# PIC18F57Q84 register map
Vendor: Microchip
Registers are 8-bit, read-write, reset 0x0 unless marked. A register's access mark holds for its fields unless they carry their own. Addresses are absolute, and some are shared; only a register's first bit layout is shown; [hi:lo] are bit positions; {n}, {i} and the like mark numbered series.

## SFR
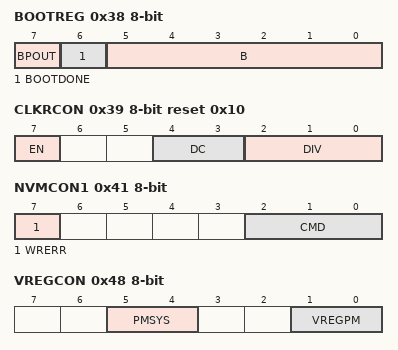
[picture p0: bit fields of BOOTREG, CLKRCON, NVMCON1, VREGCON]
0x38 BOOTREG reset not defined — (power-on value xxxxxxxx)
  [7] BPOUT, [6] BOOTDONE, [5:0] B
0x39 CLKRCON reset 0x10
  [7] EN, [4:3] DC, [2:0] DIV
0x3A CLKRCLK
  [4:0] CLK
0x40 NVMCON0 reset not defined — (power-on value -------x)
  [0] GO
0x41 NVMCON1 reset not defined — (power-on value x----xxx)
  [7] WRERR, [2:0] CMD
0x42 NVMLOCK
  [7:0] LOCK
0x43 NVMADRL
0x44 NVMADRH
0x45 NVMADRU
  [5:0] NVMADRU
0x46 NVMDATL
0x47 NVMDATH
0x48 VREGCON reset not defined — (power-on value --qq--10)
  [5:4] PMSYS ro, [1:0] VREGPM
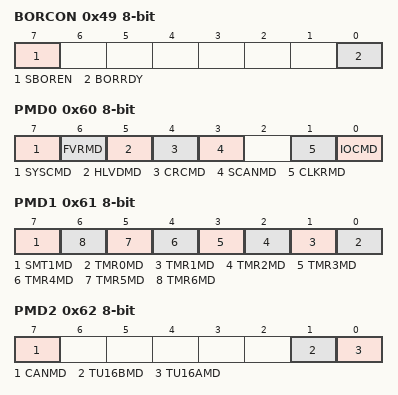
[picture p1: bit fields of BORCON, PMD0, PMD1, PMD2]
0x49 BORCON reset not defined — (power-on value 1------q)
  [7] SBOREN, [0] BORRDY ro
0x60 PMD0
  [7] SYSCMD, [6] FVRMD, [5] HLVDMD, [4] CRCMD, [3] SCANMD, [1] CLKRMD, [0] IOCMD
0x61 PMD1
  [7] SMT1MD, [n] TMR{n}MD (n=0..6)
0x62 PMD2 reset not defined — (power-on value x-----xx)
  [7] CANMD, [1] TU16BMD, [0] TU16AMD
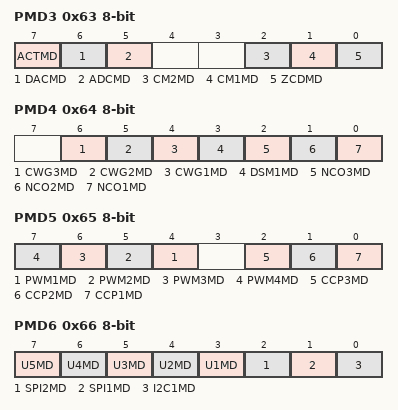
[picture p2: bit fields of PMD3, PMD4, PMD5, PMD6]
0x63 PMD3
  [7] ACTMD, [6] DACMD, [5] ADCMD, [2] CM2MD, [1] CM1MD, [0] ZCDMD
0x64 PMD4 reset not defined — (power-on value 0xxxxxxx)
  [6] CWG3MD, [5] CWG2MD, [4] CWG1MD, [3] DSM1MD, [2] NCO3MD, [1] NCO2MD, [0] NCO1MD
0x65 PMD5 reset not defined — (power-on value xxxx-xxx)
  [n+3] PWM{n}MD (n=1..4), [2] CCP3MD, [1] CCP2MD, [0] CCP1MD
0x66 PMD6 reset not defined — (power-on value xxxxxxxx)
  [n+2] U{n}MD (n=1..5), [2] SPI2MD, [1] SPI1MD, [0] I2C1MD
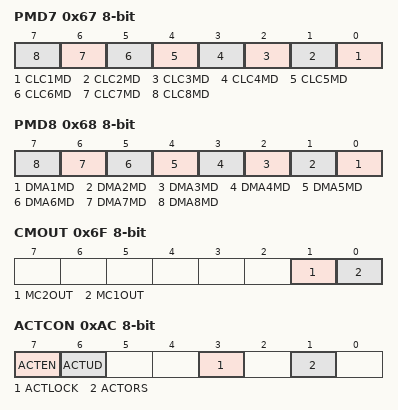
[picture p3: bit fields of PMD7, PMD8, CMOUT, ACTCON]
0x67 PMD7
  [n-1] CLC{n}MD (n=1..8)
0x68 PMD8 reset not defined — (power-on value xx000000)
  [n-1] DMA{n}MD (n=1..8)
0x6F CMOUT ro
  [1] MC2OUT, [0] MC1OUT
0xAC ACTCON
  [7] ACTEN, [6] ACTUD, [3] ACTLOCK ro, [1] ACTORS ro
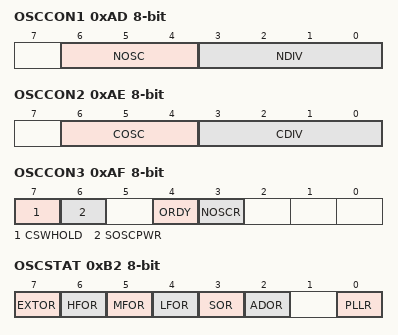
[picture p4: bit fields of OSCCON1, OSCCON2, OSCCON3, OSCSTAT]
0xAD OSCCON1 reset not defined — (power-on value -qqqqqqq)
  [6:4] NOSC, [3:0] NDIV
0xAE OSCCON2 ro reset not defined — (power-on value -qqqqqqq)
  [6:4] COSC, [3:0] CDIV
0xAF OSCCON3
  [7] CSWHOLD, [6] SOSCPWR, [4] ORDY ro, [3] NOSCR ro
0xB0 OSCTUNE
  [5:0] TUN
0xB1 OSCFRQ reset not defined — (power-on value ----q0q0)
  [3:0] HFFRQ
0xB2 OSCSTAT ro reset not defined — (power-on value qqqqqq-q)
  [7] EXTOR, [6] HFOR, [5] MFOR, [4] LFOR, [3] SOR, [2] ADOR, [0] PLLR
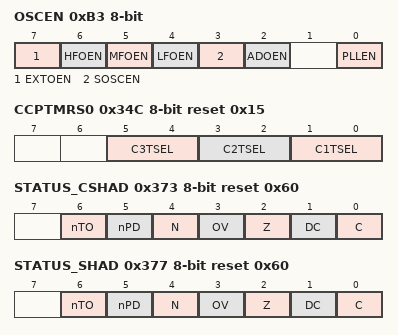
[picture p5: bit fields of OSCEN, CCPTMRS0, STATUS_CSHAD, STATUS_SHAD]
0xB3 OSCEN
  [7] EXTOEN, [6] HFOEN, [5] MFOEN, [4] LFOEN, [3] SOSCEN, [2] ADOEN, [0] PLLEN
0xB4 PRLOCK
  [0] PRLOCKED
0xB5 SCANPR reset 0x7
  [2:0] PR
{0xB5+i} DMA{i}PR reset 0x7 (i=1..6)
  [2:0] PR
0xBC DMA7PR reset not defined — (power-on value -----xxx)
  [2:0] PR
0xBD DMA8PR reset not defined — (power-on value -----xxx)
  [2:0] PR
0xBE MAINPR reset 0x7
  [2:0] PR
0xBF ISRPR reset 0x7
  [2:0] PR
0xD4 CLCDATA reset not defined — (power-on value xxxxxxxx)
  [7:0] MCLC
0x200 PPSLOCK
  [0] PPSLOCKED
0x34C CCPTMRS0 reset 0x15
  [5:4] C3TSEL, [3:2] C2TSEL, [1:0] C1TSEL
0x353 CRCOUTL
  [7:0] OUT
0x353 CRCSHFTL ro
  [7:0] SHIFT
0x353 CRCXORL
  [7:0] XOR
0x354 CRCOUTH
  [7:0] OUT
0x354 CRCSHFTH ro
  [7:0] SHIFT
0x354 CRCXORH
  [7:0] XOR
0x355 CRCOUTU
  [7:0] OUT
0x355 CRCSHFTU ro
  [7:0] SHIFT
0x355 CRCXORU
  [7:0] XOR
0x356 CRCOUTT
  [7:0] OUT
0x356 CRCSHFTT ro
  [7:0] SHIFT
0x356 CRCXORT
  [7:0] XOR
0x373 STATUS_CSHAD reset 0x60
  [6] nTO ro, [5] nPD ro, [4] N, [3] OV, [2] Z, [1] DC, [0] C
0x374 WREG_CSHAD reset not defined — (power-on value xxxxxxxx)
  [7:0] WREG
0x375 BSR_CSHAD
  [5:0] BSR
0x376 SHADCON
  [0] SHADLO
0x377 STATUS_SHAD reset 0x60
  [6] nTO ro, [5] nPD ro, [4] N, [3] OV, [2] Z, [1] DC, [0] C
0x378 WREG_SHAD reset not defined — (power-on value xxxxxxxx)
  [7:0] WREG
0x379 BSR_SHAD
  [5:0] BSR
0x37A PCLATH_SHAD
  [7:0] PCH
0x37B PCLATU_SHAD
  [4:0] PCU
{0x37C+2i} FSR{i}L_SHAD (i=0..2)
  [7:0] FSR{i}L
{0x37D+2i} FSR{i}H_SHAD (i=0..2)
  [5:0] FSR{i}H
0x382 PRODL_SHAD reset not defined — (power-on value xxxxxxxx)
  [7:0] PRODL
0x383 PRODH_SHAD reset not defined — (power-on value xxxxxxxx)
  [7:0] PRODH
0x38B TU16ATMRL
  [7:0] TMRL
0x38B TU16ACRL ro
  [7:0] CRL
0x38C TU16ATMRH
  [7:0] TMRH
0x38C TU16ACRH ro
  [7:0] CRH
0x397 TU16BTMRL
  [7:0] TMRL
0x397 TU16BCRL ro
  [7:0] CRL
0x398 TU16BTMRH
  [7:0] TMRH
0x398 TU16BCRH ro
  [7:0] CRH
0x3BB TUCHAIN reset not defined — (power-on value -------x)
  [0] CH16AB
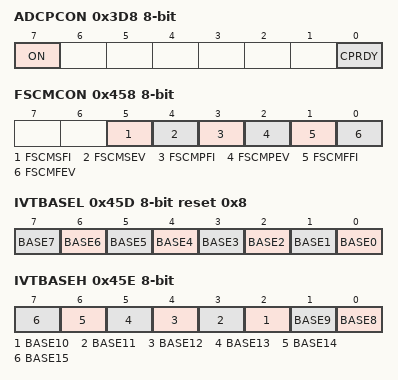
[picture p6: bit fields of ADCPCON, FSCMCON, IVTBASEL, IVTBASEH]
0x3D8 ADCPCON reset not defined — (power-on value x------x)
  [7] ON, [0] CPRDY ro
0x458 FSCMCON reset not defined — (power-on value --xxxxxx)
  [5] FSCMSFI, [4] FSCMSEV, [3] FSCMPFI, [2] FSCMPEV, [1] FSCMFFI, [0] FSCMFEV
0x459 IVTLOCK
  [0] IVTLOCKED
0x45A IVTADL reset not defined — (power-on value xxxxxxxx)
  [7:0] AD
0x45B IVTADH reset not defined — (power-on value xxxxxxxx)
  [7:0] AD
0x45C IVTADU reset not defined — (power-on value xxxxxxxx)
  [7:0] AD
0x45D IVTBASEL reset 0x8
  [n] BASE{n} (n=0..7)
0x45E IVTBASEH
  [n-8] BASE{n} (n=8..15)
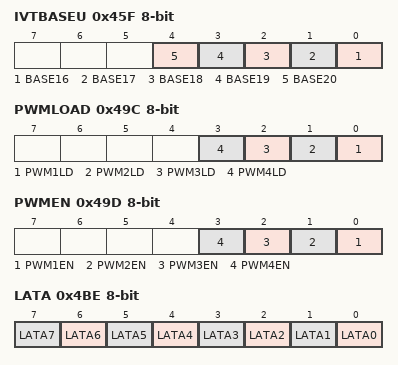
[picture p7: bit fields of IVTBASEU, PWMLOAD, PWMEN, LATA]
0x45F IVTBASEU
  [n-16] BASE{n} (n=16..20)
0x49C PWMLOAD reset not defined — (power-on value ----x000)
  [n-1] PWM{n}LD (n=1..4)
0x49D PWMEN reset not defined — (power-on value ----x000)
  [n-1] PWM{n}EN (n=1..4)
0x4BE LATA reset not defined — (power-on value xxxxxxxx)
  [n] LATA{n} (n=0..7)
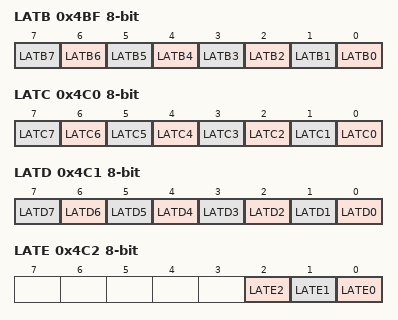
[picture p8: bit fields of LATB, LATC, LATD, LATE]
0x4BF LATB reset not defined — (power-on value xxxxxxxx)
  [n] LATB{n} (n=0..7)
0x4C0 LATC reset not defined — (power-on value xxxxxxxx)
  [n] LATC{n} (n=0..7)
0x4C1 LATD reset not defined — (power-on value xxxxxxxx)
  [n] LATD{n} (n=0..7)
0x4C2 LATE reset not defined — (power-on value -----xxx)
  [2] LATE2, [1] LATE1, [0] LATE0
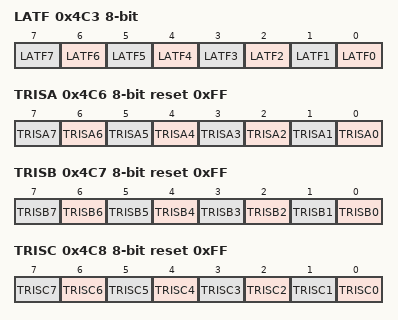
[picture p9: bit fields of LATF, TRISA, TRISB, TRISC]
0x4C3 LATF reset not defined — (power-on value xxxxxxxx)
  [n] LATF{n} (n=0..7)
0x4C6 TRISA reset 0xFF
  [n] TRISA{n} (n=0..7)
0x4C7 TRISB reset 0xFF
  [n] TRISB{n} (n=0..7)
0x4C8 TRISC reset 0xFF
  [n] TRISC{n} (n=0..7)
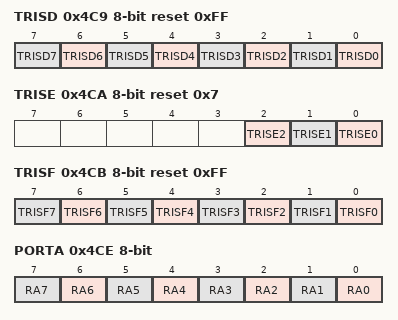
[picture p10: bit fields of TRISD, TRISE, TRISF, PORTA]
0x4C9 TRISD reset 0xFF
  [n] TRISD{n} (n=0..7)
0x4CA TRISE reset 0x7
  [2] TRISE2, [1] TRISE1, [0] TRISE0
0x4CB TRISF reset 0xFF
  [n] TRISF{n} (n=0..7)
0x4CE PORTA reset not defined — (power-on value xxxxxxxx)
  [n] RA{n} (n=0..7)
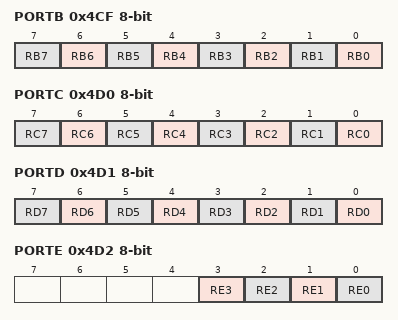
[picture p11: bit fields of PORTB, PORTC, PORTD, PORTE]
0x4CF PORTB reset not defined — (power-on value xxxxxxxx)
  [n] RB{n} (n=0..7)
0x4D0 PORTC reset not defined — (power-on value xxxxxxxx)
  [n] RC{n} (n=0..7)
0x4D1 PORTD reset not defined — (power-on value xxxxxxxx)
  [n] RD{n} (n=0..7)
0x4D2 PORTE reset not defined — (power-on value ----xxxx)
  [3] RE3 ro, [2] RE2, [1] RE1, [0] RE0
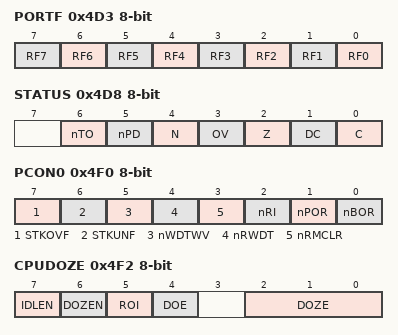
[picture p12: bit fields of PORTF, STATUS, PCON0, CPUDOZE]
0x4D3 PORTF reset not defined — (power-on value xxxxxxxx)
  [n] RF{n} (n=0..7)
0x4D8 STATUS reset not defined — (power-on value -xxxxxxx)
  [6] nTO, [5] nPD, [4] N, [3] OV, [2] Z, [1] DC, [0] C
0x4D9 FSR2L
0x4DA FSR2H
  [5:0] FSR2H
0x4DB PLUSW2 access not given reset not defined
0x4DC PREINC2 access not given reset not defined
0x4DD POSTDEC2 access not given reset not defined
0x4DE POSTINC2 access not given reset not defined
0x4DF INDF2 access not given reset not defined — (power-on value xxxxxxxx)
0x4E0 BSR
  [5:0] BSR
0x4E1 FSR1L
0x4E2 FSR1H
  [5:0] FSR1H
0x4E3 PLUSW1 access not given reset not defined
0x4E4 PREINC1 access not given reset not defined
0x4E5 POSTDEC1 access not given reset not defined
0x4E6 POSTINC1 access not given reset not defined
0x4E7 INDF1 access not given reset not defined — (power-on value xxxxxxxx)
0x4E8 WREG reset not defined — (power-on value xxxxxxxx)
0x4E9 FSR0L
0x4EA FSR0H
  [5:0] FSR0H
0x4EB PLUSW0 access not given reset not defined
0x4EC PREINC0 access not given reset not defined
0x4ED POSTDEC0 access not given reset not defined
0x4EE POSTINC0 access not given reset not defined
0x4EF INDF0 access not given reset not defined — (power-on value xxxxxxxx)
0x4F0 PCON0 reset not defined — (power-on value 0011110q)
  [7] STKOVF, [6] STKUNF, [5] nWDTWV, [4] nRWDT, [3] nRMCLR, [2] nRI, [1] nPOR, [0] nBOR
0x4F1 PCON1 reset 0x2
  [1] nMEMV
0x4F2 CPUDOZE
  [7] IDLEN, [6] DOZEN, [5] ROI, [4] DOE, [2:0] DOZE
0x4F3 PRODL reset not defined — (power-on value xxxxxxxx)
0x4F4 PRODH reset not defined — (power-on value xxxxxxxx)
0x4F5 TABLAT
0x4F6 TBLPTRL
0x4F7 TBLPTRH
0x4F8 TBLPTRU
  [5:0] TBLPTRU
0x4F9 PCL
0x4FA PCLATH
  [7:0] PCH
0x4FB PCLATU
  [4:0] PCU
0x4FC STKPTR
  [6:0] STKPTR
0x4FD TOSL reset not defined — (power-on value xxxxxxxx)
0x4FE TOSH reset not defined — (power-on value xxxxxxxx)
0x4FF TOSU reset not defined — (power-on value ---xxxxx)
  [4:0] TOSU
